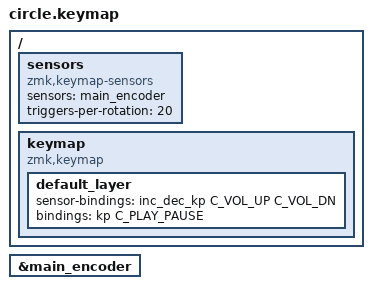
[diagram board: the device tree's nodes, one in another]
#include <behaviors.dtsi>
#include <dt-bindings/zmk/keys.h>

&main_encoder {
    status = "okay";
};

/ {
    sensors: sensors {
        compatible = "zmk,keymap-sensors";
        sensors = <&main_encoder>;
        triggers-per-rotation = <20>;
    };

    keymap {
        compatible = "zmk,keymap";

        default_layer {
            sensor-bindings = <&inc_dec_kp C_VOL_UP C_VOL_DN>;
            bindings = < &kp C_PLAY_PAUSE >;
        };
    };
};
